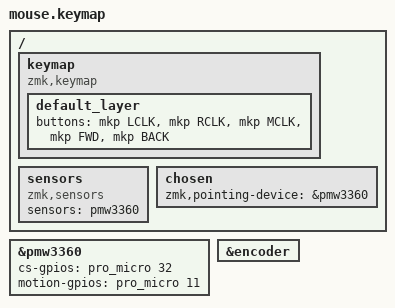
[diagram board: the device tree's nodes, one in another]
#include <behaviors.dtsi>
#include <dt-bindings/zmk/keys.h>
#include <dt-bindings/zmk/mouse.h>

/ {
    keymap {
        compatible = "zmk,keymap"; 

        default_layer {
            buttons = <
                &mkp LCLK  &mkp RCLK  &mkp MCLK  &mkp FWD  &mkp BACK
            >;
        };
    };

    sensors {
        compatible = "zmk,sensors";
        sensors = <&pmw3360>;
    };

    chosen {
        zmk,pointing-device = &pmw3360;
    };
};

&pmw3360 {
    status = "okay";
    cs-gpios = <&pro_micro 32 0>;  // Use pin P1.00 (D6) as CS
    motion-gpios = <&pro_micro 11 0>; // Use pin P0.11 (D7) as MOTION
};

&encoder {
    status = "okay";
};
